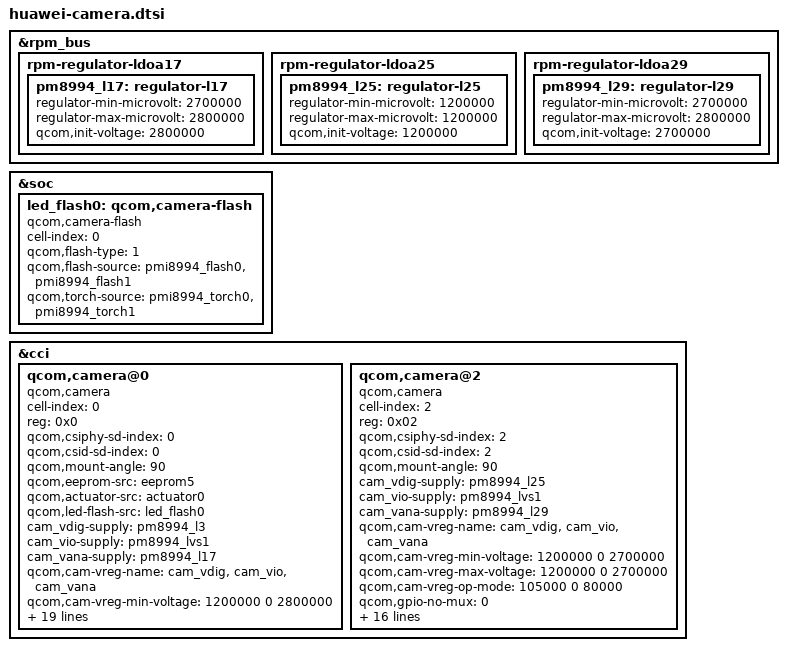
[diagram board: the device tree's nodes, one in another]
/*
 * Copyright (c) 2015, The Linux Foundation. All rights reserved.
 *
 * This program is free software; you can redistribute it and/or modify
 * it under the terms of the GNU General Public License version 2 and
 * only version 2 as published by the Free Software Foundation.
 *
 * This program is distributed in the hope that it will be useful,
 * but WITHOUT ANY WARRANTY; without even the implied warranty of
 * MERCHANTABILITY or FITNESS FOR A PARTICULAR PURPOSE.  See the
 * GNU General Public License for more details.
 */

&rpm_bus {
	/delete-property/ rpm-regulator-ldoa17;
	/delete-property/ rpm-regulator-ldoa25;
	/delete-property/ rpm-regulator-ldoa29;
	rpm-regulator-ldoa17 {
		status = "okay";
		pm8994_l17: regulator-l17 {
			regulator-min-microvolt = <2700000>;
			regulator-max-microvolt = <2800000>;
			qcom,init-voltage = <2800000>;
			status = "okay";
		};
	};
	rpm-regulator-ldoa25 {
		status = "okay";
		pm8994_l25: regulator-l25 {
			regulator-min-microvolt = <1200000>;
			regulator-max-microvolt = <1200000>;
			qcom,init-voltage = <1200000>;
			status = "okay";
		};
	};
	rpm-regulator-ldoa29 {
		status = "okay";
		pm8994_l29: regulator-l29 {
			regulator-min-microvolt = <2700000>;
			regulator-max-microvolt = <2800000>;
			qcom,init-voltage = <2700000>;
			status = "okay";
		};
	};
};

&soc {
	led_flash0: qcom,camera-flash {
		cell-index = <0>;
		compatible = "qcom,camera-flash";
		qcom,flash-type = <1>;
		qcom,flash-source = <&pmi8994_flash0 &pmi8994_flash1>;
		qcom,torch-source = <&pmi8994_torch0 &pmi8994_torch1>;
	};
};

&cci {
	/delete-property/ qcom,actuator@1;

	/delete-property/ qcom,ois@0;

	/delete-property/ com,eeprom@0;

	/delete-property/ qcom,eeprom@1;

	/delete-property/ qcom,eeprom@2;

	/delete-property/ qcom,camera@0;

	/delete-property/ qcom,camera@1;

	/delete-property/ qcom,camera@2;

	qcom,camera@0 {
		cell-index = <0>;
		compatible = "qcom,camera";
		reg = <0x0>;
		qcom,csiphy-sd-index = <0>;
		qcom,csid-sd-index = <0>;
		qcom,mount-angle = <90>;
		qcom,eeprom-src = <&eeprom5>;
		qcom,actuator-src = <&actuator0>;
		qcom,led-flash-src = <&led_flash0>;
		cam_vdig-supply = <&pm8994_l3>;
		cam_vio-supply = <&pm8994_lvs1>;
		cam_vana-supply = <&pm8994_l17>;
		qcom,cam-vreg-name = "cam_vdig", "cam_vio", "cam_vana";
		qcom,cam-vreg-min-voltage = <1200000 0 2800000>;
		qcom,cam-vreg-max-voltage = <1200000 0 2800000>;
		qcom,cam-vreg-op-mode = <105000 0 80000>;
		qcom,gpio-no-mux = <0>;
		pinctrl-names = "cam_default", "cam_suspend";
		pinctrl-0 = <&cam_sensor_mclk0_active &cam_sensor_rear_active>;
		pinctrl-1 = <&cam_sensor_mclk0_suspend &cam_sensor_rear_suspend>;
		gpios = <&msm_gpio 13 0>,
			<&msm_gpio 92 0>,
			<&msm_gpio 91 0>;
		qcom,gpio-reset = <1>;
		qcom,gpio-standby = <2>;
		qcom,gpio-req-tbl-num = <0 1 2>;
		qcom,gpio-req-tbl-flags = <1 0 0>;
		qcom,gpio-req-tbl-label = "CAMIF_MCLK0",
					  "CAM_RESET0",
					  "CAM_STANDBY0";
		qcom,sensor-position = <0>;
		qcom,sensor-mode = <0>;
		qcom,cci-master = <0>;
		status = "ok";
		clocks = <&clock_mmss clk_mclk0_clk_src>,
				<&clock_mmss clk_camss_mclk0_clk>;
		clock-names = "cam_src_clk", "cam_clk";
	};

	qcom,camera@2 {
		cell-index = <2>;
		compatible = "qcom,camera";
		reg = <0x02>;
		qcom,csiphy-sd-index = <2>;
		qcom,csid-sd-index = <2>;
		qcom,mount-angle = <90>;
		cam_vdig-supply = <&pm8994_l25>;
		cam_vio-supply = <&pm8994_lvs1>;
		cam_vana-supply = <&pm8994_l29>;
		qcom,cam-vreg-name = "cam_vdig", "cam_vio", "cam_vana";
		qcom,cam-vreg-min-voltage = <1200000 0 2700000>;
		qcom,cam-vreg-max-voltage = <1200000 0 2700000>;
		qcom,cam-vreg-op-mode = <105000 0 80000>;
		qcom,gpio-no-mux = <0>;
		pinctrl-names = "cam_default", "cam_suspend";
		pinctrl-0 = <&cam_sensor_mclk2_active &cam_sensor_front_active>;
		pinctrl-1 = <&cam_sensor_mclk2_suspend &cam_sensor_front_suspend>;
		gpios = <&msm_gpio 15 0>,
			<&msm_gpio 104 0>,
			<&msm_gpio 105 0>;
		qcom,gpio-reset = <1>;
		qcom,gpio-standby = <2>;
		qcom,gpio-req-tbl-num = <0 1 2>;
		qcom,gpio-req-tbl-flags = <1 0 0>;
		qcom,gpio-req-tbl-label = "CAMIF_MCLK2",
					  "CAM_RESET2",
					  "CAM_STANDBY2";
		qcom,sensor-position = <1>;
		qcom,sensor-mode = <0>;
		qcom,cci-master = <1>;
		status = "ok";
		clocks = <&clock_mmss clk_mclk2_clk_src>,
			<&clock_mmss clk_camss_mclk2_clk>;
		clock-names = "cam_src_clk", "cam_clk";
	};
};
